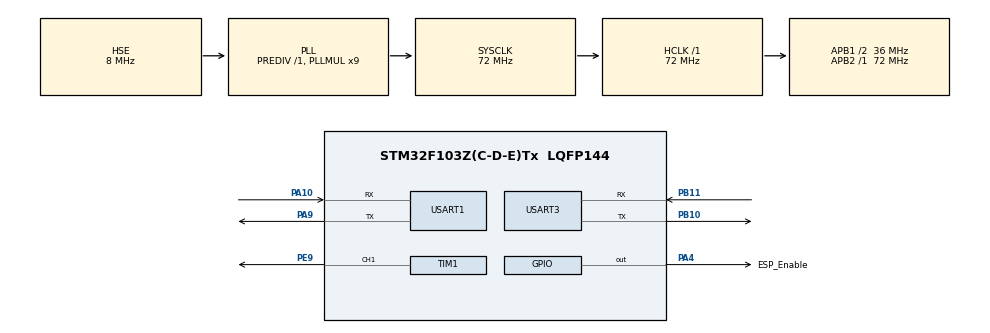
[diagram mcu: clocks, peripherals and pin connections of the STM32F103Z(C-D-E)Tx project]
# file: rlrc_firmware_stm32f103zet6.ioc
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Dma.Request0=TIM1_CH1
Dma.Request1=USART3_RX
Dma.TIM1_CH1.0.Direction=DMA_MEMORY_TO_PERIPH
Dma.TIM1_CH1.0.Instance=DMA1_Channel2
Dma.TIM1_CH1.0.MemDataAlignment=DMA_MDATAALIGN_HALFWORD
Dma.TIM1_CH1.0.MemInc=DMA_MINC_ENABLE
Dma.TIM1_CH1.0.Mode=DMA_NORMAL
Dma.TIM1_CH1.0.PeriphDataAlignment=DMA_PDATAALIGN_HALFWORD
Dma.TIM1_CH1.0.PeriphInc=DMA_PINC_DISABLE
Dma.TIM1_CH1.0.Priority=DMA_PRIORITY_LOW
Dma.USART3_RX.1.Direction=DMA_PERIPH_TO_MEMORY
Dma.USART3_RX.1.Instance=DMA1_Channel3
Dma.USART3_RX.1.MemDataAlignment=DMA_MDATAALIGN_BYTE
Dma.USART3_RX.1.MemInc=DMA_MINC_ENABLE
Dma.USART3_RX.1.Mode=DMA_CIRCULAR
Dma.USART3_RX.1.PeriphDataAlignment=DMA_PDATAALIGN_BYTE
Dma.USART3_RX.1.PeriphInc=DMA_PINC_DISABLE
Dma.USART3_RX.1.Priority=DMA_PRIORITY_LOW
Mcu.Family=STM32F1
Mcu.Name=STM32F103Z(C-D-E)Tx
Mcu.Package=LQFP144
NVIC.DMA1_Channel2_IRQn=true\:0\:0\:false\:false\:true\:false\:true\:true
NVIC.DMA1_Channel3_IRQn=true\:0\:0\:false\:false\:true\:false\:true\:true
NVIC.PriorityGroup=NVIC_PRIORITYGROUP_4
NVIC.TIM1_UP_IRQn=true\:0\:0\:false\:false\:true\:true\:true\:true
NVIC.USART3_IRQn=true\:0\:0\:false\:false\:true\:true\:true\:true
OSC_IN.Mode=HSE-External-Oscillator
OSC_IN.Signal=RCC_OSC_IN
OSC_OUT.Mode=HSE-External-Oscillator
OSC_OUT.Signal=RCC_OSC_OUT
PA10.Mode=Asynchronous
PA10.Signal=USART1_RX
PA13.Mode=Serial_Wire
PA13.Signal=SYS_JTMS-SWDIO
PA14.Mode=Serial_Wire
PA14.Signal=SYS_JTCK-SWCLK
PA4.GPIO_Label=ESP_Enable
PA4.PinState=GPIO_PIN_RESET
PA4.Signal=GPIO_Output
PA9.Mode=Asynchronous
PA9.Signal=USART1_TX
PB10.Mode=Asynchronous
PB10.Signal=USART3_TX
PB11.Mode=Asynchronous
PB11.Signal=USART3_RX
PC14-OSC32_IN.Mode=LSE-External-Oscillator
PC14-OSC32_IN.Signal=RCC_OSC32_IN
PC15-OSC32_OUT.Mode=LSE-External-Oscillator
PC15-OSC32_OUT.Signal=RCC_OSC32_OUT
PE9.GPIO_Speed=GPIO_SPEED_FREQ_HIGH
PE9.Signal=S_TIM1_CH1
ProjectManager.HeapSize=0x200
ProjectManager.StackSize=0x400
ProjectManager.TargetToolchain=CMake
RCC.AHBFreq_Value=72000000
RCC.APB1CLKDivider=RCC_HCLK_DIV2
RCC.APB1Freq_Value=36000000
RCC.APB1TimFreq_Value=72000000
RCC.APB2Freq_Value=72000000
RCC.APB2TimFreq_Value=72000000
RCC.HCLKFreq_Value=72000000
RCC.PLLMUL=RCC_PLL_MUL9
RCC.PLLSourceVirtual=RCC_PLLSOURCE_HSE
RCC.SYSCLKFreq_VALUE=72000000
RCC.SYSCLKSource=RCC_SYSCLKSOURCE_PLLCLK
RCC.USBFreq_Value=72000000
SH.S_TIM1_CH1.0=TIM1_CH1,PWM Generation1 CH1
TIM1.Channel-PWM\ Generation1\ CH1=TIM_CHANNEL_1
TIM1.Period=89
USART1.VirtualMode=VM_ASYNC
USART3.VirtualMode=VM_ASYNC
VP_TIM1_VS_ClockSourceINT.Mode=Internal
board=custom

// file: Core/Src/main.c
/* USER CODE BEGIN Header */
/**
 ******************************************************************************
 * @file           : main.c
 * @brief          : Main program body
 ******************************************************************************
 * @attention
 *
 * Copyright (c) 2025 STMicroelectronics.
 * All rights reserved.
 *
 * This software is licensed under terms that can be found in the LICENSE file
 * in the root directory of this software component.
 * If no LICENSE file comes with this software, it is provided AS-IS.
 *
 ******************************************************************************
 */
/* USER CODE END Header */
#include "main.h"
#include "dma.h"
#include "tim.h"
#include "usart.h"
#include "gpio.h"

/* USER CODE BEGIN Includes */
#include "maincxx.hpp"
#include "retarget.h"
extern void ws2812b_dma_complete_callback();
/* USER CODE END Includes */

void SystemClock_Config(void);

int main(void)
{

  /* MCU Configuration--------------------------------------------------------*/

  /* Reset of all peripherals, Initializes the Flash interface and the Systick. */
  HAL_Init();

  /* Configure the system clock */
  SystemClock_Config();

  /* Initialize all configured peripherals */
  MX_GPIO_Init();
  MX_DMA_Init();
  MX_TIM1_Init();
  MX_USART1_UART_Init();
  MX_USART3_UART_Init();
  /* USER CODE BEGIN 2 */
    RetargetInit(&huart1);
  /* USER CODE END 2 */

  /* Infinite loop */
  /* USER CODE BEGIN WHILE */
    maincxx();
    // while (1)
    // {
    /* USER CODE END WHILE */

    /* USER CODE BEGIN 3 */
    // }
  /* USER CODE END 3 */
}

void SystemClock_Config(void)
{
  RCC_OscInitTypeDef RCC_OscInitStruct = {0};
  RCC_ClkInitTypeDef RCC_ClkInitStruct = {0};

  /** Initializes the RCC Oscillators according to the specified parameters
  * in the RCC_OscInitTypeDef structure.
  */
  RCC_OscInitStruct.OscillatorType = RCC_OSCILLATORTYPE_HSE;
  RCC_OscInitStruct.HSEState = RCC_HSE_ON;
  RCC_OscInitStruct.HSEPredivValue = RCC_HSE_PREDIV_DIV1;
  RCC_OscInitStruct.HSIState = RCC_HSI_ON;
  RCC_OscInitStruct.PLL.PLLState = RCC_PLL_ON;
  RCC_OscInitStruct.PLL.PLLSource = RCC_PLLSOURCE_HSE;
  RCC_OscInitStruct.PLL.PLLMUL = RCC_PLL_MUL9;
  if (HAL_RCC_OscConfig(&RCC_OscInitStruct) != HAL_OK)
  {
    Error_Handler();
  }

  /** Initializes the CPU, AHB and APB buses clocks
  */
  RCC_ClkInitStruct.ClockType = RCC_CLOCKTYPE_HCLK|RCC_CLOCKTYPE_SYSCLK
                              |RCC_CLOCKTYPE_PCLK1|RCC_CLOCKTYPE_PCLK2;
  RCC_ClkInitStruct.SYSCLKSource = RCC_SYSCLKSOURCE_PLLCLK;
  RCC_ClkInitStruct.AHBCLKDivider = RCC_SYSCLK_DIV1;
  RCC_ClkInitStruct.APB1CLKDivider = RCC_HCLK_DIV2;
  RCC_ClkInitStruct.APB2CLKDivider = RCC_HCLK_DIV1;

  if (HAL_RCC_ClockConfig(&RCC_ClkInitStruct, FLASH_LATENCY_2) != HAL_OK)
  {
    Error_Handler();
  }
}

/* USER CODE BEGIN 4 */

/**
  * @brief  PWM 脉冲完成回调 (在 DMA 模式下，这表示整个缓冲区传输完成)
  * @param  htim TIM 句柄
  * @retval None
  */
void HAL_TIM_PWM_PulseFinishedCallback(TIM_HandleTypeDef *htim)
{
    // 检查是否是 TIM1 触发的
    if (htim->Instance == TIM1)
    {
        // 调用我们的 C++ 跳板函数
        ws2812b_dma_complete_callback();
    }
}

/* USER CODE END 4 */

void Error_Handler(void)
{
    __disable_irq();
    while (1) {
    }
}
